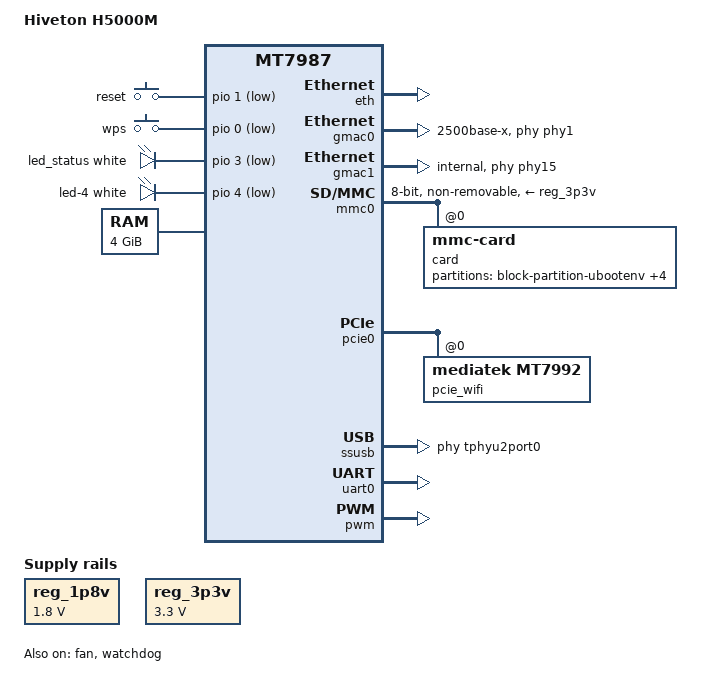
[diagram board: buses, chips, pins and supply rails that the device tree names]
// SPDX-License-Identifier: (GPL-2.0 OR MIT)

/dts-v1/;
#include "mt7987a.dtsi"
#include <dt-bindings/input/input.h>
#include <dt-bindings/leds/common.h>

/ {
	model = "Hiveton H5000M";
	compatible = "hiveton,h5000m",
		     "mediatek,mt7987a",
		     "mediatek,mt7987";

	aliases {
		label-mac-device = &gmac1;
		led-boot = &led_status;
		led-failsafe = &led_status;
		led-running = &led_status;
		led-upgrade = &led_status;
		serial0 = &uart0;
	};

	chosen {
		bootargs = "console=ttyS0,115200n1 \
			    earlycon=uart8250,mmio32,0x11000000 \
			    pci=pcie_bus_perf";
		rootdisk = <&emmc_rootfs>;
		stdout-path = "serial0:115200n8";
	};

	gpio-keys {
		compatible = "gpio-keys";

		reset {
			label = "reset";
			linux,code = <KEY_RESTART>;
			gpios = <&pio 1 GPIO_ACTIVE_LOW>;
			debounce-interval = <10>;
		};

		wps {
			label = "wps";
			linux,code = <KEY_WPS_BUTTON>;
			gpios = <&pio 0 GPIO_ACTIVE_LOW>;
			debounce-interval = <10>;
		};
	};

	gpio-leds {
		compatible = "gpio-leds";

		led_status: led-3 {
			color = <LED_COLOR_ID_WHITE>;
			function = LED_FUNCTION_WLAN_2GHZ;
			gpios = <&pio 3 GPIO_ACTIVE_LOW>;
		};

		led-4 {
			color = <LED_COLOR_ID_WHITE>;
			function = LED_FUNCTION_WLAN_5GHZ;
			gpios = <&pio 4 GPIO_ACTIVE_LOW>;
		};
	};

	memory {
		device_type = "memory";
		reg = <0x0 0x40000000 0x1 0x00000000>;
	};

	reg_1p8v: regulator-1p8v {
		compatible = "regulator-fixed";
		regulator-name = "fixed-1.8V";
		regulator-min-microvolt = <1800000>;
		regulator-max-microvolt = <1800000>;
		regulator-boot-on;
		regulator-always-on;
	};

	reg_3p3v: regulator-3p3v {
		compatible = "regulator-fixed";
		regulator-name = "fixed-3.3V";
		regulator-min-microvolt = <3300000>;
		regulator-max-microvolt = <3300000>;
		regulator-boot-on;
		regulator-always-on;
	};
};

&eth {
	status = "okay";
};

&fan {
	pwms = <&pwm 1 50000 0>;
	/delete-property/ cooling-levels;
	/delete-property/ #cooling-cells;
	/delete-property/ #thermal-sensor-cells;
	status = "okay";
};

&cpu_thermal {
	cooling-maps {
		/*
		 * pwm-fan drives the fan at MAX_PWM during its kernel probe, so
		 * it remains at full speed until userspace fancontrol takes over.
		 * Do not bind the kernel thermal governor to the PWM fan.
		 */
		/delete-node/ cpu-active-high;
		/delete-node/ cpu-active-low;
		/delete-node/ cpu-passive;
	};
};

&gmac0 {
	phy-mode = "2500base-x";
	phy-handle = <&phy1>;
	status = "okay";
};

&gmac1 {
	phy-mode = "internal";
	phy-handle = <&phy15>;
	status = "okay";
};

&hnat {
	mtketh-wan = "eth1";
	mtketh-lan = "eth0";
	mtketh-lan2 = "hnat";
	mtketh-ppd = "hnat";
	mtketh-max-gmac = <2>;
};

&phy1 {
	compatible = "ethernet-phy-ieee802.3-c45";
	reg = <1>;
	reset-gpios = <&pio 42 GPIO_ACTIVE_LOW>;
	reset-assert-us = <100000>;
	reset-deassert-us = <100000>;
	interrupt-parent = <&pio>;
	interrupts = <41 IRQ_TYPE_LEVEL_LOW>;
};

&phy15 {
	compatible = "ethernet-phy-ieee802.3-c45";
	reg = <15>;
	pinctrl-names = "i2p5gbe-led";
	pinctrl-0 = <&i2p5gbe_led0_pins>;
};

&mmc0 {
	pinctrl-names = "default", "state_uhs";
	pinctrl-0 = <&mmc_pins_default>;
	pinctrl-1 = <&mmc_pins_uhs>;
	bus-width = <8>;
	max-frequency = <52000000>;
	cap-mmc-highspeed;
	mmc-ddr-1_8v;
	vmmc-supply = <&reg_3p3v>;
	vqmmc-supply = <&reg_1p8v>;
	non-removable;
	no-sd;
	no-sdio;
	status = "okay";

	#address-cells = <1>;
	#size-cells = <0>;

	card@0 {
		compatible = "mmc-card";
		reg = <0>;

		block {
			compatible = "block-device";

			partitions {
				compatible = "gpt-partitions";

				block-partition-ubootenv {
					partname = "ubootenv";

					nvmem-layout {
						compatible = "u-boot,env-layout";
					};
				};

				block-partition-factory {
					partname = "factory";

					nvmem-layout {
						compatible = "fixed-layout";
						#address-cells = <1>;
						#size-cells = <1>;

						eeprom_factory_0: eeprom@0 {
							reg = <0x0 0x1000>;
						};

						macaddr_factory_24: macaddr@24 {
							compatible = "mac-base";
							reg = <0x24 0x6>;
							#nvmem-cell-cells = <1>;
						};

						macaddr_factory_2a: macaddr@2a {
							compatible = "mac-base";
							reg = <0x2a 0x6>;
							#nvmem-cell-cells = <1>;
						};
					};
				};

				block-partition-fip {
					partname = "fip";
				};

				block-partition-recovery {
					partname = "recovery";
				};

				emmc_rootfs: block-partition-production {
					partname = "production";
				};
			};
		};
	};
};

&pcie0 {
	pinctrl-names = "default";
	pinctrl-0 = <&pcie0_pins>;
	status = "okay";

	pcie@0,0 {
		reg = <0x0000 0 0 0 0>;
		#address-cells = <3>;
		#size-cells = <2>;

		pcie_wifi: wifi@0,0 {
			compatible = "mediatek,mt7992";
			reg = <0x0000 0 0 0 0>;
			nvmem-cells = <&eeprom_factory_0>;
			nvmem-cell-names = "eeprom";
		};
	};
};

&pcie1 {
	pinctrl-names = "default";
	pinctrl-0 = <&pcie1_pins>;
	status = "disabled";
};

&ssusb {
	mediatek,u3p-dis-msk = <0>;
	phys = <&tphyu2port0 PHY_TYPE_USB2>,
	       <&tphyu3port0 PHY_TYPE_USB3>;
	status = "okay";
};

&uart0 {
	pinctrl-names = "default";
	pinctrl-0 = <&uart0_pins>;
	status = "okay";
};

&watchdog {
	status = "okay";
};

&pwm {
	pinctrl-names = "default";
	pinctrl-0 = <&pwm_fan_pins>;
	status = "okay";
};
